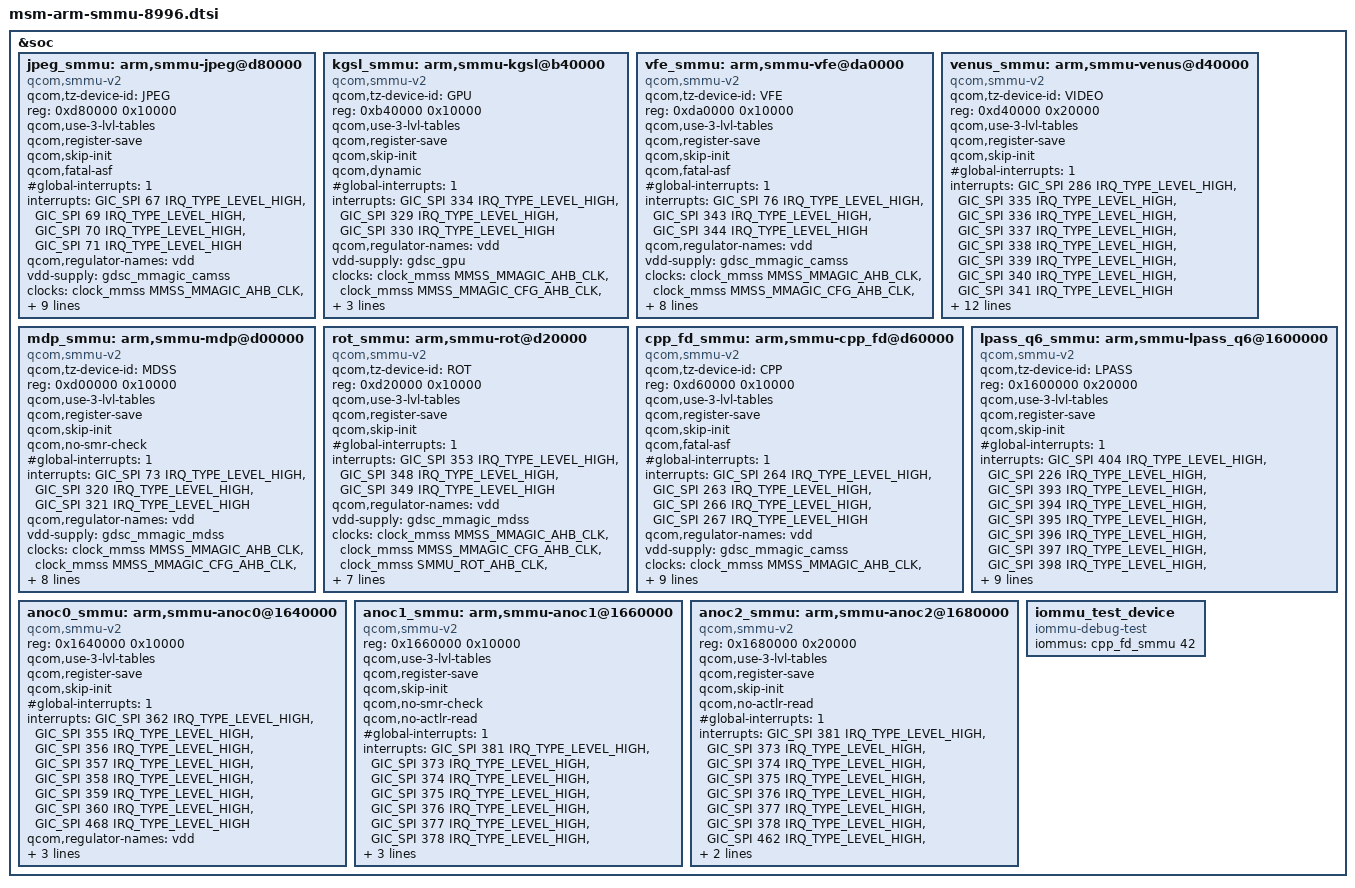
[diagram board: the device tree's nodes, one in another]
/* Copyright (c) 2015-2016, The Linux Foundation. All rights reserved.
 *
 * This program is free software; you can redistribute it and/or modify
 * it under the terms of the GNU General Public License version 2 and
 * only version 2 as published by the Free Software Foundation.
 *
 * This program is distributed in the hope that it will be useful,
 * but WITHOUT ANY WARRANTY; without even the implied warranty of
 * MERCHANTABILITY or FITNESS FOR A PARTICULAR PURPOSE.  See the
 * GNU General Public License for more details.
 */

#include <dt-bindings/msm/msm-bus-ids.h>
#include <dt-bindings/interrupt-controller/arm-gic.h>

&soc {
	jpeg_smmu: arm,smmu-jpeg@d80000 {
		compatible = "qcom,smmu-v2";
		qcom,tz-device-id = "JPEG";
		reg = <0xd80000 0x10000>;
		#iommu-cells = <1>;
		status = "ok";
		qcom,use-3-lvl-tables;
		qcom,register-save;
		qcom,skip-init;
		qcom,fatal-asf;
		#global-interrupts = <1>;
		interrupts = <GIC_SPI 67 IRQ_TYPE_LEVEL_HIGH>,
			<GIC_SPI 69 IRQ_TYPE_LEVEL_HIGH>,
			<GIC_SPI 70 IRQ_TYPE_LEVEL_HIGH>,
			<GIC_SPI 71 IRQ_TYPE_LEVEL_HIGH>;
		qcom,regulator-names = "vdd";
		vdd-supply = <&gdsc_mmagic_camss>;
		clocks = <&clock_mmss MMSS_MMAGIC_AHB_CLK>,
			<&clock_mmss MMSS_MMAGIC_CFG_AHB_CLK>,
			<&clock_mmss SMMU_JPEG_AHB_CLK>,
			<&clock_mmss SMMU_JPEG_AXI_CLK>,
			<&clock_mmss MMAGIC_CAMSS_AXI_CLK>;
		clock-names = "mmagic_ahb_clk", "mmagic_cfg_ahb_clk",
			"jpeg_ahb_clk", "jpeg_axi_clk",
			"mmagic_camss_axi_clk";
		#clock-cells = <1>;
		qcom,msm-bus,name = "smmu-bus-client-jpeg";
		qcom,msm-bus,num-cases = <2>;
		qcom,msm-bus,num-paths = <1>;
		qcom,msm-bus,vectors-KBps =
					<62 512 0 0>,
					<62 512 0 1000>;
	};

	kgsl_smmu: arm,smmu-kgsl@b40000 {
		compatible = "qcom,smmu-v2";
		qcom,tz-device-id = "GPU";
		reg = <0xb40000 0x10000>;
		#iommu-cells = <1>;
		status = "ok";
		qcom,use-3-lvl-tables;
		qcom,register-save;
		qcom,skip-init;
		qcom,dynamic;
		#global-interrupts = <1>;
		interrupts = <GIC_SPI 334 IRQ_TYPE_LEVEL_HIGH>,
			<GIC_SPI 329 IRQ_TYPE_LEVEL_HIGH>,
			<GIC_SPI 330 IRQ_TYPE_LEVEL_HIGH>;
		qcom,regulator-names = "vdd";
		vdd-supply = <&gdsc_gpu>;
		clocks = <&clock_mmss MMSS_MMAGIC_AHB_CLK>,
			<&clock_mmss MMSS_MMAGIC_CFG_AHB_CLK>,
			<&clock_gpu GPU_AHB_CLK>,
			<&clock_gcc GCC_MMSS_BIMC_GFX_CLK>,
			<&clock_gcc GCC_BIMC_GFX_CLK>;
		clock-names = "mmagic_ahb_clk", "mmagic_cfg_ahb_clk", "gpu_ahb_clk",
			"gcc_mmss_bimc_gfx_clk", "gcc_bimc_gfx_clk";
		#clock-cells = <1>;
	};

	vfe_smmu: arm,smmu-vfe@da0000 {
		compatible = "qcom,smmu-v2";
		qcom,tz-device-id = "VFE";
		reg = <0xda0000 0x10000>;
		#iommu-cells = <1>;
		status = "ok";
		qcom,use-3-lvl-tables;
		qcom,register-save;
		qcom,skip-init;
		qcom,fatal-asf;
		#global-interrupts = <1>;
		interrupts = <GIC_SPI 76 IRQ_TYPE_LEVEL_HIGH>,
			<GIC_SPI 343 IRQ_TYPE_LEVEL_HIGH>,
			<GIC_SPI 344 IRQ_TYPE_LEVEL_HIGH>;
		qcom,regulator-names = "vdd";
		vdd-supply = <&gdsc_mmagic_camss>;
		clocks = <&clock_mmss MMSS_MMAGIC_AHB_CLK>,
			<&clock_mmss MMSS_MMAGIC_CFG_AHB_CLK>,
			<&clock_mmss SMMU_VFE_AHB_CLK>,
			<&clock_mmss SMMU_VFE_AXI_CLK>,
			<&clock_mmss MMAGIC_CAMSS_AXI_CLK>;
		clock-names = "mmagic_ahb_clk", "mmagic_cfg_ahb_clk",
			"vfe_ahb_clk", "vfe_axi_clk",
			"mmagic_camss_axi_clk";
		#clock-cells = <1>;
		qcom,msm-bus,name = "smmu-bus-client-vfe";
		qcom,msm-bus,num-cases = <2>;
		qcom,msm-bus,num-paths = <1>;
		qcom,msm-bus,vectors-KBps =
					<29 512 0 0>,
					<29 512 0 1000>;
	};

	venus_smmu: arm,smmu-venus@d40000 {
		compatible = "qcom,smmu-v2";
		qcom,tz-device-id = "VIDEO";
		reg = <0xd40000 0x20000>;
		#iommu-cells = <1>;
		status = "ok";
		qcom,use-3-lvl-tables;
		qcom,register-save;
		qcom,skip-init;
		#global-interrupts = <1>;
		interrupts = <GIC_SPI 286 IRQ_TYPE_LEVEL_HIGH>,
			<GIC_SPI 335 IRQ_TYPE_LEVEL_HIGH>,
			<GIC_SPI 336 IRQ_TYPE_LEVEL_HIGH>,
			<GIC_SPI 337 IRQ_TYPE_LEVEL_HIGH>,
			<GIC_SPI 338 IRQ_TYPE_LEVEL_HIGH>,
			<GIC_SPI 339 IRQ_TYPE_LEVEL_HIGH>,
			<GIC_SPI 340 IRQ_TYPE_LEVEL_HIGH>,
			<GIC_SPI 341 IRQ_TYPE_LEVEL_HIGH>;
		qcom,regulator-names = "vdd";
		vdd-supply = <&gdsc_mmagic_video>;
		clocks = <&clock_mmss MMSS_MMAGIC_AHB_CLK>,
			<&clock_mmss MMSS_MMAGIC_CFG_AHB_CLK>,
			<&clock_mmss SMMU_VIDEO_AHB_CLK>,
			<&clock_mmss SMMU_VIDEO_AXI_CLK>,
			<&clock_mmss MMAGIC_VIDEO_AXI_CLK>;
		clock-names = "mmagic_ahb_clk", "mmagic_cfg_ahb_clk",
			"video_ahb_clk", "video_axi_clk",
			"mmagic_video_axi_clk";
		#clock-cells = <1>;
		qcom,msm-bus,name = "smmu-bus-client-video-p0";
		qcom,msm-bus,num-cases = <2>;
		qcom,msm-bus,num-paths = <1>;
		qcom,msm-bus,vectors-KBps =
					<63 512 0 0>,
					<63 512 0 1000>;
	};

	mdp_smmu: arm,smmu-mdp@d00000 {
		compatible = "qcom,smmu-v2";
		qcom,tz-device-id = "MDSS";
		reg = <0xd00000 0x10000>;
		#iommu-cells = <1>;
		status = "ok";
		qcom,use-3-lvl-tables;
		qcom,register-save;
		qcom,skip-init;
		qcom,no-smr-check;
		#global-interrupts = <1>;
		interrupts = <GIC_SPI 73 IRQ_TYPE_LEVEL_HIGH>,
			<GIC_SPI 320 IRQ_TYPE_LEVEL_HIGH>,
			<GIC_SPI 321 IRQ_TYPE_LEVEL_HIGH>;
		qcom,regulator-names = "vdd";
		vdd-supply = <&gdsc_mmagic_mdss>;
		clocks = <&clock_mmss MMSS_MMAGIC_AHB_CLK>,
			<&clock_mmss MMSS_MMAGIC_CFG_AHB_CLK>,
			<&clock_mmss SMMU_MDP_AHB_CLK>,
			<&clock_mmss SMMU_MDP_AXI_CLK>,
			<&clock_mmss MMAGIC_MDSS_AXI_CLK>;
		clock-names = "mmagic_ahb_clk", "mmagic_cfg_ahb_clk",
			"mdp_ahb_clk", "mdp_axi_clk",
			"mmagic_mdss_axi_clk";
		#clock-cells = <1>;
		qcom,msm-bus,name = "smmu-bus-client-mdp-port0";
		qcom,msm-bus,num-cases = <2>;
		qcom,msm-bus,num-paths = <1>;
		qcom,msm-bus,vectors-KBps =
					<22 512 0 0>,
					<22 512 0 1000>;
	};

	rot_smmu: arm,smmu-rot@d20000 {
		compatible = "qcom,smmu-v2";
		qcom,tz-device-id = "ROT";
		reg = <0xd20000 0x10000>;
		#iommu-cells = <1>;
		status = "ok";
		qcom,use-3-lvl-tables;
		qcom,register-save;
		qcom,skip-init;
		#global-interrupts = <1>;
		interrupts = <GIC_SPI 353 IRQ_TYPE_LEVEL_HIGH>,
			<GIC_SPI 348 IRQ_TYPE_LEVEL_HIGH>,
			<GIC_SPI 349 IRQ_TYPE_LEVEL_HIGH>;
		qcom,regulator-names = "vdd";
		vdd-supply = <&gdsc_mmagic_mdss>;
		clocks = <&clock_mmss MMSS_MMAGIC_AHB_CLK>,
			<&clock_mmss MMSS_MMAGIC_CFG_AHB_CLK>,
			<&clock_mmss SMMU_ROT_AHB_CLK>,
			<&clock_mmss SMMU_ROT_AXI_CLK>,
			<&clock_mmss MMAGIC_MDSS_AXI_CLK>;
		clock-names = "mmagic_ahb_clk", "mmagic_cfg_ahb_clk",
			"rot_ahb_clk", "rot_axi_clk",
			"mmagic_mdss_axi_clk";
		#clock-cells = <1>;
		qcom,msm-bus,name = "smmu-bus-client-rotator";
		qcom,msm-bus,num-cases = <2>;
		qcom,msm-bus,num-paths = <1>;
		qcom,msm-bus,vectors-KBps =
					<25 512 0 0>,
					<25 512 0 1000>;
	};

	cpp_fd_smmu: arm,smmu-cpp_fd@d60000 {
		compatible = "qcom,smmu-v2";
		qcom,tz-device-id = "CPP";
		reg = <0xd60000 0x10000>;
		#iommu-cells = <1>;
		status = "ok";
		qcom,use-3-lvl-tables;
		qcom,register-save;
		qcom,skip-init;
		qcom,fatal-asf;
		#global-interrupts = <1>;
		interrupts = <GIC_SPI 264 IRQ_TYPE_LEVEL_HIGH>,
			<GIC_SPI 263 IRQ_TYPE_LEVEL_HIGH>,
			<GIC_SPI 266 IRQ_TYPE_LEVEL_HIGH>,
			<GIC_SPI 267 IRQ_TYPE_LEVEL_HIGH>;
		qcom,regulator-names = "vdd";
		vdd-supply = <&gdsc_mmagic_camss>;
		clocks = <&clock_mmss MMSS_MMAGIC_AHB_CLK>,
			<&clock_mmss MMSS_MMAGIC_CFG_AHB_CLK>,
			<&clock_mmss SMMU_CPP_AHB_CLK>,
			<&clock_mmss SMMU_CPP_AXI_CLK>,
			<&clock_mmss MMAGIC_CAMSS_AXI_CLK>;
		clock-names = "mmagic_ahb_clk", "mmagic_cfg_ahb_clk",
			"cpp_ahb_clk", "cpp_axi_clk",
			"mmagic_camss_axi_clk";
		#clock-cells = <1>;
		qcom,msm-bus,name = "smmu-bus-client-cpp";
		qcom,msm-bus,num-cases = <2>;
		qcom,msm-bus,num-paths = <1>;
		qcom,msm-bus,vectors-KBps =
					<106 512 0 0>,
					<106 512 0 1000>;
	};

	lpass_q6_smmu: arm,smmu-lpass_q6@1600000 {
		compatible = "qcom,smmu-v2";
		qcom,tz-device-id = "LPASS";
		reg = <0x1600000 0x20000>;
		#iommu-cells = <1>;
		status = "ok";
		qcom,use-3-lvl-tables;
		qcom,register-save;
		qcom,skip-init;
		#global-interrupts = <1>;
		interrupts = <GIC_SPI 404 IRQ_TYPE_LEVEL_HIGH>,
			<GIC_SPI 226 IRQ_TYPE_LEVEL_HIGH>,
			<GIC_SPI 393 IRQ_TYPE_LEVEL_HIGH>,
			<GIC_SPI 394 IRQ_TYPE_LEVEL_HIGH>,
			<GIC_SPI 395 IRQ_TYPE_LEVEL_HIGH>,
			<GIC_SPI 396 IRQ_TYPE_LEVEL_HIGH>,
			<GIC_SPI 397 IRQ_TYPE_LEVEL_HIGH>,
			<GIC_SPI 398 IRQ_TYPE_LEVEL_HIGH>,
			<GIC_SPI 399 IRQ_TYPE_LEVEL_HIGH>,
			<GIC_SPI 400 IRQ_TYPE_LEVEL_HIGH>,
			<GIC_SPI 401 IRQ_TYPE_LEVEL_HIGH>,
			<GIC_SPI 402 IRQ_TYPE_LEVEL_HIGH>,
			<GIC_SPI 403 IRQ_TYPE_LEVEL_HIGH>;
		qcom,regulator-names = "vdd";
		vdd-supply = <&gdsc_hlos1_vote_lpass_adsp>;
		clocks = <&clock_gcc GCC_HLOS1_VOTE_LPASS_ADSP_SMMU_CLK>;
		clock-names = "lpass_q6_smmu_clocks";
		#clock-cells = <1>;
	};

	anoc0_smmu: arm,smmu-anoc0@1640000 {
		compatible = "qcom,smmu-v2";
		reg = <0x1640000 0x10000>;
		#iommu-cells = <0>;
		status = "ok";
		qcom,use-3-lvl-tables;
		qcom,register-save;
		qcom,skip-init;
		#global-interrupts = <1>;
		interrupts = <GIC_SPI 362 IRQ_TYPE_LEVEL_HIGH>,
			<GIC_SPI 355 IRQ_TYPE_LEVEL_HIGH>,
			<GIC_SPI 356 IRQ_TYPE_LEVEL_HIGH>,
			<GIC_SPI 357 IRQ_TYPE_LEVEL_HIGH>,
			<GIC_SPI 358 IRQ_TYPE_LEVEL_HIGH>,
			<GIC_SPI 359 IRQ_TYPE_LEVEL_HIGH>,
			<GIC_SPI 360 IRQ_TYPE_LEVEL_HIGH>,
			<GIC_SPI 468 IRQ_TYPE_LEVEL_HIGH>;
		qcom,regulator-names = "vdd";
		vdd-supply = <&gdsc_aggre0_noc>;
		clocks = <&clock_gcc GCC_SMMU_AGGRE0_AXI_CLK>,
			<&clock_gcc GCC_SMMU_AGGRE0_AHB_CLK>;
		clock-names = "smmu_aggre0_axi_clk", "smmu_aggre0_ahb_clk";
		#clock-cells = <1>;
	};

	anoc1_smmu: arm,smmu-anoc1@1660000 {
		compatible = "qcom,smmu-v2";
		reg = <0x1660000 0x10000>;
		#iommu-cells = <1>;
		status = "ok";
		qcom,use-3-lvl-tables;
		qcom,register-save;
		qcom,skip-init;
		qcom,no-smr-check;
		qcom,no-actlr-read;
		#global-interrupts = <1>;
		interrupts = <GIC_SPI 381 IRQ_TYPE_LEVEL_HIGH>,
			<GIC_SPI 373 IRQ_TYPE_LEVEL_HIGH>,
			<GIC_SPI 374 IRQ_TYPE_LEVEL_HIGH>,
			<GIC_SPI 375 IRQ_TYPE_LEVEL_HIGH>,
			<GIC_SPI 376 IRQ_TYPE_LEVEL_HIGH>,
			<GIC_SPI 377 IRQ_TYPE_LEVEL_HIGH>,
			<GIC_SPI 378 IRQ_TYPE_LEVEL_HIGH>,
			<GIC_SPI 462 IRQ_TYPE_LEVEL_HIGH>,
			<GIC_SPI 463 IRQ_TYPE_LEVEL_HIGH>;
		clocks = <&clock_rpmcc RPM_SMD_AGGR2_NOC_CLK>;
		clock-names = "smmu_aggre2_noc_clk";
		#clock-cells = <1>;
	};

	anoc2_smmu: arm,smmu-anoc2@1680000 {
		compatible = "qcom,smmu-v2";
		reg = <0x1680000 0x20000>;
		#iommu-cells = <1>;
		status = "ok";
		qcom,use-3-lvl-tables;
		qcom,register-save;
		qcom,skip-init;
		qcom,no-actlr-read;
		#global-interrupts = <1>;
		interrupts = <GIC_SPI 381 IRQ_TYPE_LEVEL_HIGH>,
			<GIC_SPI 373 IRQ_TYPE_LEVEL_HIGH>,
			<GIC_SPI 374 IRQ_TYPE_LEVEL_HIGH>,
			<GIC_SPI 375 IRQ_TYPE_LEVEL_HIGH>,
			<GIC_SPI 376 IRQ_TYPE_LEVEL_HIGH>,
			<GIC_SPI 377 IRQ_TYPE_LEVEL_HIGH>,
			<GIC_SPI 378 IRQ_TYPE_LEVEL_HIGH>,
			<GIC_SPI 462 IRQ_TYPE_LEVEL_HIGH>,
			<GIC_SPI 463 IRQ_TYPE_LEVEL_HIGH>;
		clocks = <&clock_rpmcc RPM_SMD_AGGR2_NOC_CLK>;
		clock-names = "smmu_aggre2_noc_clk";
		#clock-cells = <1>;
	};
};

&soc {
	iommu_test_device {
		compatible = "iommu-debug-test";
		/*
		 * 42 shouldn't be used by anyone on the cpp_fd_smmu.  We just
		 * need _something_ here to get this node recognized by the
		 * SMMU driver. Our test uses ATOS, which doesn't use SIDs
		 * anyways, so using a dummy value is ok.
		 */
		iommus = <&cpp_fd_smmu 42>;
	};
};
